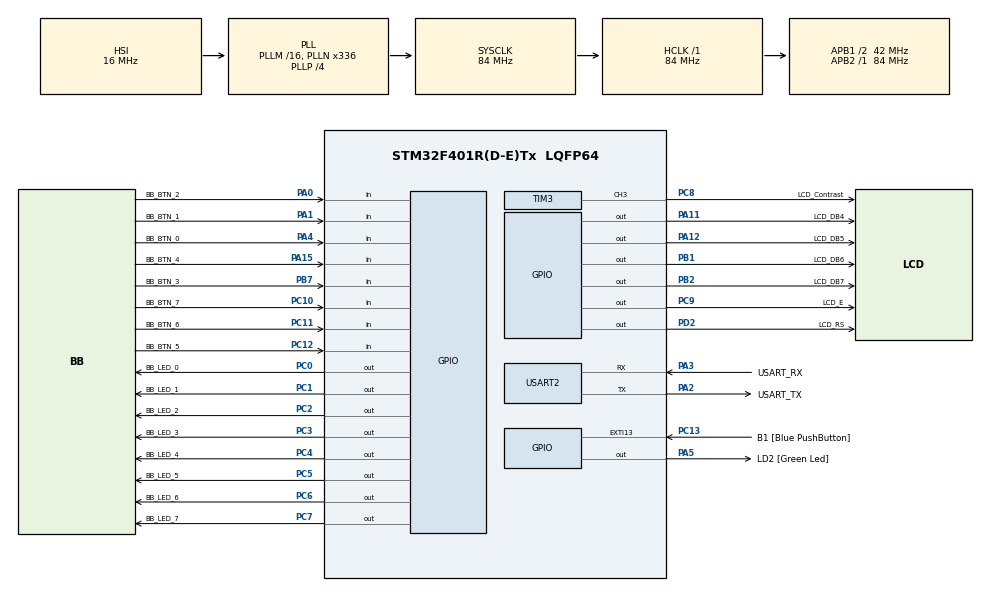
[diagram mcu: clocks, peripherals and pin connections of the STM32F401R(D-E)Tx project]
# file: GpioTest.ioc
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Mcu.Family=STM32F4
Mcu.Name=STM32F401R(D-E)Tx
Mcu.Package=LQFP64
NVIC.PriorityGroup=NVIC_PRIORITYGROUP_0
PA0-WKUP.GPIO_Label=BB_BTN_2
PA0-WKUP.GPIO_PuPd=GPIO_PULLDOWN
PA0-WKUP.Signal=GPIO_Input
PA1.GPIO_Label=BB_BTN_1
PA1.GPIO_PuPd=GPIO_PULLDOWN
PA1.Signal=GPIO_Input
PA11.GPIO_Label=LCD_DB4
PA11.GPIO_Speed=GPIO_SPEED_FREQ_VERY_HIGH
PA11.Signal=GPIO_Output
PA12.GPIO_Label=LCD_DB5
PA12.GPIO_Speed=GPIO_SPEED_FREQ_VERY_HIGH
PA12.Signal=GPIO_Output
PA13.GPIO_Label=TMS
PA13.Mode=Serial_Wire
PA13.Signal=SYS_JTMS-SWDIO
PA14.GPIO_Label=TCK
PA14.Mode=Serial_Wire
PA14.Signal=SYS_JTCK-SWCLK
PA15.GPIO_Label=BB_BTN_4
PA15.GPIO_PuPd=GPIO_PULLDOWN
PA15.Signal=GPIO_Input
PA2.GPIO_Label=USART_TX
PA2.GPIO_Mode=GPIO_MODE_AF_PP
PA2.GPIO_PuPd=GPIO_NOPULL
PA2.GPIO_Speed=GPIO_SPEED_FREQ_LOW
PA2.Mode=Asynchronous
PA2.Signal=USART2_TX
PA3.GPIO_Label=USART_RX
PA3.GPIO_Mode=GPIO_MODE_AF_PP
PA3.GPIO_PuPd=GPIO_NOPULL
PA3.GPIO_Speed=GPIO_SPEED_FREQ_LOW
PA3.Mode=Asynchronous
PA3.Signal=USART2_RX
PA4.GPIO_Label=BB_BTN_0
PA4.GPIO_PuPd=GPIO_PULLDOWN
PA4.Signal=GPIO_Input
PA5.GPIO_Label=LD2 [Green Led]
PA5.GPIO_Mode=GPIO_MODE_OUTPUT_PP
PA5.GPIO_PuPd=GPIO_NOPULL
PA5.GPIO_Speed=GPIO_SPEED_FREQ_LOW
PA5.Signal=GPIO_Output
PB1.GPIO_Label=LCD_DB6
PB1.GPIO_Speed=GPIO_SPEED_FREQ_VERY_HIGH
PB1.Signal=GPIO_Output
PB2.GPIO_Label=LCD_DB7
PB2.GPIO_Speed=GPIO_SPEED_FREQ_VERY_HIGH
PB2.Signal=GPIO_Output
PB3.GPIO_Label=SWO
PB3.Signal=SYS_JTDO-SWO
PB7.GPIO_Label=BB_BTN_3
PB7.GPIO_PuPd=GPIO_PULLDOWN
PB7.Signal=GPIO_Input
PC0.GPIO_Label=BB_LED_0
PC0.Signal=GPIO_Output
PC1.GPIO_Label=BB_LED_1
PC1.Signal=GPIO_Output
PC10.GPIO_Label=BB_BTN_7
PC10.GPIO_PuPd=GPIO_PULLDOWN
PC10.Signal=GPIO_Input
PC11.GPIO_Label=BB_BTN_6
PC11.GPIO_PuPd=GPIO_PULLDOWN
PC11.Signal=GPIO_Input
PC12.GPIO_Label=BB_BTN_5
PC12.GPIO_PuPd=GPIO_PULLDOWN
PC12.Signal=GPIO_Input
PC13-ANTI_TAMP.GPIO_Label=B1 [Blue PushButton]
PC13-ANTI_TAMP.GPIO_ModeDefaultEXTI=GPIO_MODE_IT_FALLING
PC13-ANTI_TAMP.GPIO_PuPd=GPIO_NOPULL
PC13-ANTI_TAMP.Signal=GPXTI13
PC14-OSC32_IN.Mode=LSE-External-Oscillator
PC14-OSC32_IN.Signal=RCC_OSC32_IN
PC15-OSC32_OUT.Mode=LSE-External-Oscillator
PC15-OSC32_OUT.Signal=RCC_OSC32_OUT
PC2.GPIO_Label=BB_LED_2
PC2.Signal=GPIO_Output
PC3.GPIO_Label=BB_LED_3
PC3.Signal=GPIO_Output
PC4.GPIO_Label=BB_LED_4
PC4.Signal=GPIO_Output
PC5.GPIO_Label=BB_LED_5
PC5.Signal=GPIO_Output
PC6.GPIO_Label=BB_LED_6
PC6.Signal=GPIO_Output
PC7.GPIO_Label=BB_LED_7
PC7.Signal=GPIO_Output
PC8.GPIO_Label=LCD_Contrast
PC8.Signal=S_TIM3_CH3
PC9.GPIO_Label=LCD_E
PC9.GPIO_Speed=GPIO_SPEED_FREQ_VERY_HIGH
PC9.PinState=GPIO_PIN_RESET
PC9.Signal=GPIO_Output
PD2.GPIO_Label=LCD_RS
PD2.GPIO_Speed=GPIO_SPEED_FREQ_VERY_HIGH
PD2.Signal=GPIO_Output
PH0\ -\ OSC_IN.Mode=HSE-External-Clock-Source
PH0\ -\ OSC_IN.Signal=RCC_OSC_IN
PH1\ -\ OSC_OUT.Mode=HSE-External-Clock-Source
PH1\ -\ OSC_OUT.Signal=RCC_OSC_OUT
ProjectManager.HeapSize=0x200
ProjectManager.StackSize=0x400
ProjectManager.TargetToolchain=STM32CubeIDE
RCC.48MHZClocksFreq_Value=48000000
RCC.AHBFreq_Value=84000000
RCC.APB1CLKDivider=RCC_HCLK_DIV2
RCC.APB1Freq_Value=42000000
RCC.APB1TimFreq_Value=84000000
RCC.APB2Freq_Value=84000000
RCC.APB2TimFreq_Value=84000000
RCC.CortexFreq_Value=84000000
RCC.HCLKFreq_Value=84000000
RCC.HSE_VALUE=8000000
RCC.HSI_VALUE=16000000
RCC.PLLN=336
RCC.PLLP=RCC_PLLP_DIV4
RCC.PLLQ=7
RCC.SYSCLKFreq_VALUE=84000000
RCC.SYSCLKSource=RCC_SYSCLKSOURCE_PLLCLK
RCC.VCOOutputFreq_Value=336000000
SH.S_TIM3_CH3.0=TIM3_CH3,PWM Generation3 CH3
TIM3.Channel-PWM\ Generation3\ CH3=TIM_CHANNEL_3
TIM3.Period=100
TIM3.Prescaler=1
TIM3.Pulse-PWM\ Generation3\ CH3=30
USART2.VirtualMode=VM_ASYNC
VP_TIM3_VS_ClockSourceINT.Mode=Internal
board=NUCLEO-F401RE

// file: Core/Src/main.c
/* USER CODE BEGIN Header */
/**
  ******************************************************************************
  * @file           : main.c
  * @brief          : Main program body
  ******************************************************************************
  * @attention
  *
  * Copyright (c) 2024 STMicroelectronics.
  * All rights reserved.
  *
  * This software is licensed under terms that can be found in the LICENSE file
  * in the root directory of this software component.
  * If no LICENSE file comes with this software, it is provided AS-IS.
  *
  ******************************************************************************
  */
/* USER CODE END Header */
#include "main.h"
#include "tim.h"
#include "usart.h"
#include "gpio.h"

void SystemClock_Config(void);

int main(void)
{

  /* MCU Configuration--------------------------------------------------------*/

  /* Reset of all peripherals, Initializes the Flash interface and the Systick. */
  HAL_Init();

  /* Configure the system clock */
  SystemClock_Config();

  /* Initialize all configured peripherals */
  MX_GPIO_Init();
  MX_USART2_UART_Init();
  MX_TIM3_Init();
  /* USER CODE BEGIN 2 */

  // Calling test program LCD
  extern void runLcdTest();
  runLcdTest();

  /* USER CODE END 2 */

  /* Infinite loop */
  while (1)
  {

  }
}

void SystemClock_Config(void)
{
  RCC_OscInitTypeDef RCC_OscInitStruct = {0};
  RCC_ClkInitTypeDef RCC_ClkInitStruct = {0};

  /** Configure the main internal regulator output voltage
  */
  __HAL_RCC_PWR_CLK_ENABLE();
  __HAL_PWR_VOLTAGESCALING_CONFIG(PWR_REGULATOR_VOLTAGE_SCALE2);

  /** Initializes the RCC Oscillators according to the specified parameters
  * in the RCC_OscInitTypeDef structure.
  */
  RCC_OscInitStruct.OscillatorType = RCC_OSCILLATORTYPE_HSI;
  RCC_OscInitStruct.HSIState = RCC_HSI_ON;
  RCC_OscInitStruct.HSICalibrationValue = RCC_HSICALIBRATION_DEFAULT;
  RCC_OscInitStruct.PLL.PLLState = RCC_PLL_ON;
  RCC_OscInitStruct.PLL.PLLSource = RCC_PLLSOURCE_HSI;
  RCC_OscInitStruct.PLL.PLLM = 16;
  RCC_OscInitStruct.PLL.PLLN = 336;
  RCC_OscInitStruct.PLL.PLLP = RCC_PLLP_DIV4;
  RCC_OscInitStruct.PLL.PLLQ = 7;
  if (HAL_RCC_OscConfig(&RCC_OscInitStruct) != HAL_OK)
  {
    Error_Handler();
  }

  /** Initializes the CPU, AHB and APB buses clocks
  */
  RCC_ClkInitStruct.ClockType = RCC_CLOCKTYPE_HCLK|RCC_CLOCKTYPE_SYSCLK
                              |RCC_CLOCKTYPE_PCLK1|RCC_CLOCKTYPE_PCLK2;
  RCC_ClkInitStruct.SYSCLKSource = RCC_SYSCLKSOURCE_PLLCLK;
  RCC_ClkInitStruct.AHBCLKDivider = RCC_SYSCLK_DIV1;
  RCC_ClkInitStruct.APB1CLKDivider = RCC_HCLK_DIV2;
  RCC_ClkInitStruct.APB2CLKDivider = RCC_HCLK_DIV1;

  if (HAL_RCC_ClockConfig(&RCC_ClkInitStruct, FLASH_LATENCY_2) != HAL_OK)
  {
    Error_Handler();
  }
}

void Error_Handler(void)
{
  __disable_irq();
  while (1)
  {
  }
}
